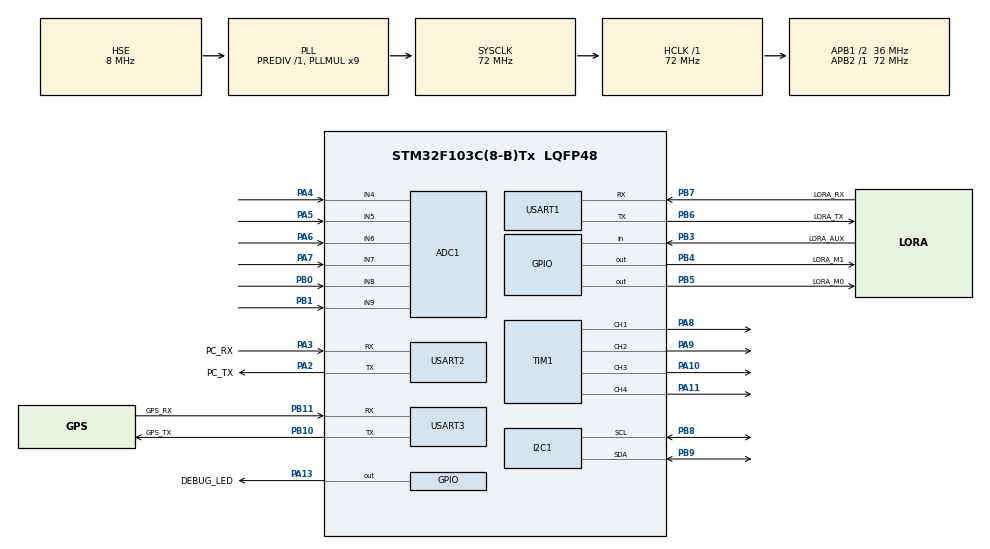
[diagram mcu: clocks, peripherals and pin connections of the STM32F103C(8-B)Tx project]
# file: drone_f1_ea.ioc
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ADC1.Channel-0\#ChannelRegularConversion=ADC_CHANNEL_4
ADC1.NbrOfConversion=1
ADC1.NbrOfConversionFlag=1
ADC1.Rank-0\#ChannelRegularConversion=1
ADC1.SamplingTime-0\#ChannelRegularConversion=ADC_SAMPLETIME_239CYCLES_5
ADC1.master=1
Dma.I2C1_RX.3.Direction=DMA_PERIPH_TO_MEMORY
Dma.I2C1_RX.3.Instance=DMA1_Channel7
Dma.I2C1_RX.3.MemDataAlignment=DMA_MDATAALIGN_BYTE
Dma.I2C1_RX.3.MemInc=DMA_MINC_ENABLE
Dma.I2C1_RX.3.Mode=DMA_NORMAL
Dma.I2C1_RX.3.PeriphDataAlignment=DMA_PDATAALIGN_BYTE
Dma.I2C1_RX.3.PeriphInc=DMA_PINC_DISABLE
Dma.I2C1_RX.3.Priority=DMA_PRIORITY_LOW
Dma.Request0=USART1_RX
Dma.Request1=USART2_RX
Dma.Request2=USART3_RX
Dma.Request3=I2C1_RX
Dma.USART1_RX.0.Direction=DMA_PERIPH_TO_MEMORY
Dma.USART1_RX.0.Instance=DMA1_Channel5
Dma.USART1_RX.0.MemDataAlignment=DMA_MDATAALIGN_BYTE
Dma.USART1_RX.0.MemInc=DMA_MINC_ENABLE
Dma.USART1_RX.0.Mode=DMA_CIRCULAR
Dma.USART1_RX.0.PeriphDataAlignment=DMA_PDATAALIGN_BYTE
Dma.USART1_RX.0.PeriphInc=DMA_PINC_DISABLE
Dma.USART1_RX.0.Priority=DMA_PRIORITY_LOW
Dma.USART2_RX.1.Direction=DMA_PERIPH_TO_MEMORY
Dma.USART2_RX.1.Instance=DMA1_Channel6
Dma.USART2_RX.1.MemDataAlignment=DMA_MDATAALIGN_BYTE
Dma.USART2_RX.1.MemInc=DMA_MINC_ENABLE
Dma.USART2_RX.1.Mode=DMA_CIRCULAR
Dma.USART2_RX.1.PeriphDataAlignment=DMA_PDATAALIGN_BYTE
Dma.USART2_RX.1.PeriphInc=DMA_PINC_DISABLE
Dma.USART2_RX.1.Priority=DMA_PRIORITY_LOW
Dma.USART3_RX.2.Direction=DMA_PERIPH_TO_MEMORY
Dma.USART3_RX.2.Instance=DMA1_Channel3
Dma.USART3_RX.2.MemDataAlignment=DMA_MDATAALIGN_BYTE
Dma.USART3_RX.2.MemInc=DMA_MINC_ENABLE
Dma.USART3_RX.2.Mode=DMA_CIRCULAR
Dma.USART3_RX.2.PeriphDataAlignment=DMA_PDATAALIGN_BYTE
Dma.USART3_RX.2.PeriphInc=DMA_PINC_DISABLE
Dma.USART3_RX.2.Priority=DMA_PRIORITY_LOW
FREERTOS.BinarySemaphores01=pc_rx_smphr,Dynamic,NULL;lora_rx_smphr,Dynamic,NULL;mpu9265_smphr,Dynamic,NULL;lora_tx_smphr,Dynamic,NULL
FREERTOS.Queues01=pc_rx_q,16,uart_data_t,0,Dynamic,NULL,NULL;pc_tx_q,16,uart_data_t,0,Dynamic,NULL,NULL;lora_rx_q,16,uart_data_t,0,Dynamic,NULL,NULL;lora_tx_q,16,uart_data_t,0,Dynamic,NULL,NULL
FREERTOS.Tasks01=periodicTask,-2,64,PeriodicTask,As weak,NULL,Dynamic,NULL,NULL;gpsTask,-1,64,GPSTask,As weak,NULL,Dynamic,NULL,NULL;motorControlTas,1,64,MotorControlTask,As weak,NULL,Dynamic,NULL,NULL;mpu9265Task,0,128,MPU9265Task,As weak,NULL,Dynamic,NULL,NULL;loraRxManager,2,128,LORARxManager,As weak,NULL,Dynamic,NULL,NULL;loraTxManager,1,64,LORATxManager,As weak,NULL,Dynamic,NULL,NULL;loraCommManager,2,64,LORACommunicationManager,As weak,NULL,Dynamic,NULL,NULL;pcRxManager,2,128,PCRxManager,As weak,NULL,Dynamic,NULL,NULL;pcTxManager,0,64,PCTxManager,As weak,NULL,Dynamic,NULL,NULL;pcCommManager,1,64,PcCommunicationManager,As weak,NULL,Dynamic,NULL,NULL;batteryTask,-2,64,BatteryTask,As weak,NULL,Dynamic,NULL,NULL
FREERTOS.configCHECK_FOR_STACK_OVERFLOW=0
FREERTOS.configMINIMAL_STACK_SIZE=64
FREERTOS.configTOTAL_HEAP_SIZE=6144
I2C1.I2C_Mode=I2C_Fast
Mcu.Family=STM32F1
Mcu.Name=STM32F103C(8-B)Tx
Mcu.Package=LQFP48
NVIC.DMA1_Channel3_IRQn=true\:5\:0\:false\:false\:true\:true\:false\:true
NVIC.DMA1_Channel5_IRQn=true\:5\:0\:false\:false\:true\:true\:false\:true
NVIC.DMA1_Channel6_IRQn=true\:5\:0\:false\:false\:true\:true\:false\:true
NVIC.DMA1_Channel7_IRQn=true\:5\:0\:false\:false\:true\:true\:false\:true
NVIC.I2C1_EV_IRQn=true\:5\:0\:false\:false\:true\:true\:true\:true
NVIC.PriorityGroup=NVIC_PRIORITYGROUP_4
NVIC.TIM4_IRQn=true\:0\:0\:false\:false\:true\:false\:false\:true
NVIC.TimeBase=TIM4_IRQn
NVIC.TimeBaseIP=TIM4
NVIC.USART1_IRQn=true\:8\:0\:true\:false\:true\:false\:true\:true
NVIC.USART2_IRQn=true\:9\:0\:true\:false\:true\:false\:true\:true
PA10.Signal=S_TIM1_CH3
PA11.Signal=S_TIM1_CH4
PA13.GPIO_Label=DEBUG_LED
PA13.Signal=GPIO_Output
PA2.GPIO_Label=PC_TX
PA2.Mode=Asynchronous
PA2.Signal=USART2_TX
PA3.GPIO_Label=PC_RX
PA3.Mode=Asynchronous
PA3.Signal=USART2_RX
PA4.Signal=ADCx_IN4
PA5.Signal=ADCx_IN5
PA6.Signal=ADCx_IN6
PA7.Signal=ADCx_IN7
PA8.Signal=S_TIM1_CH1
PA9.Signal=S_TIM1_CH2
PB0.Signal=ADCx_IN8
PB1.Signal=ADCx_IN9
PB10.GPIO_Label=GPS_TX
PB10.Mode=Asynchronous
PB10.Signal=USART3_TX
PB11.GPIO_Label=GPS_RX
PB11.Mode=Asynchronous
PB11.Signal=USART3_RX
PB3.GPIO_Label=LORA_AUX
PB3.Signal=GPIO_Input
PB4.GPIO_Label=LORA_M1
PB4.Signal=GPIO_Output
PB5.GPIO_Label=LORA_M0
PB5.Signal=GPIO_Output
PB6.GPIO_Label=LORA_TX
PB6.Mode=Asynchronous
PB6.Signal=USART1_TX
PB7.GPIO_Label=LORA_RX
PB7.Mode=Asynchronous
PB7.Signal=USART1_RX
PB8.Mode=I2C
PB8.Signal=I2C1_SCL
PB9.GPIO_Mode=GPIO_MODE_AF_OD
PB9.Mode=I2C
PB9.Signal=I2C1_SDA
PD0-OSC_IN.Mode=HSE-External-Oscillator
PD0-OSC_IN.Signal=RCC_OSC_IN
PD1-OSC_OUT.Mode=HSE-External-Oscillator
PD1-OSC_OUT.Signal=RCC_OSC_OUT
ProjectManager.HeapSize=0x200
ProjectManager.StackSize=0x400
ProjectManager.TargetToolchain=STM32CubeIDE
RCC.ADCPresc=RCC_ADCPCLK2_DIV8
RCC.AHBFreq_Value=72000000
RCC.APB1CLKDivider=RCC_HCLK_DIV2
RCC.APB1Freq_Value=36000000
RCC.APB1TimFreq_Value=72000000
RCC.APB2Freq_Value=72000000
RCC.APB2TimFreq_Value=72000000
RCC.HCLKFreq_Value=72000000
RCC.PLLMUL=RCC_PLL_MUL9
RCC.PLLSourceVirtual=RCC_PLLSOURCE_HSE
RCC.SYSCLKFreq_VALUE=72000000
RCC.SYSCLKSource=RCC_SYSCLKSOURCE_PLLCLK
RCC.USBFreq_Value=72000000
SH.ADCx_IN4.0=ADC1_IN4,IN4
SH.ADCx_IN5.0=ADC1_IN5,IN5
SH.ADCx_IN6.0=ADC1_IN6,IN6
SH.ADCx_IN7.0=ADC1_IN7,IN7
SH.ADCx_IN8.0=ADC1_IN8,IN8
SH.ADCx_IN9.0=ADC1_IN9,IN9
SH.S_TIM1_CH1.0=TIM1_CH1,PWM Generation1 CH1
SH.S_TIM1_CH2.0=TIM1_CH2,PWM Generation2 CH2
SH.S_TIM1_CH3.0=TIM1_CH3,PWM Generation3 CH3
SH.S_TIM1_CH4.0=TIM1_CH4,PWM Generation4 CH4
TIM1.Channel-PWM\ Generation1\ CH1=TIM_CHANNEL_1
TIM1.Channel-PWM\ Generation2\ CH2=TIM_CHANNEL_2
TIM1.Channel-PWM\ Generation3\ CH3=TIM_CHANNEL_3
TIM1.Channel-PWM\ Generation4\ CH4=TIM_CHANNEL_4
USART1.VirtualMode=VM_ASYNC
USART2.VirtualMode=VM_ASYNC
USART3.VirtualMode=VM_ASYNC
VP_FREERTOS_VS_CMSIS_V1.Mode=CMSIS_V1
VP_SYS_VS_ND.Mode=No_Debug
VP_SYS_VS_tim4.Mode=TIM4
board=custom

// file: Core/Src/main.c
/* USER CODE BEGIN Header */
/**
  ******************************************************************************
  * @file           : main.c
  * @brief          : Main program body
  ******************************************************************************
  * @attention
  *
  * <h2><center>&copy; Copyright (c) 2020 STMicroelectronics.
  * All rights reserved.</center></h2>
  *
  * This software component is licensed by ST under BSD 3-Clause license,
  * the "License"; You may not use this file except in compliance with the
  * License. You may obtain a copy of the License at:
  *                        opensource.org/licenses/BSD-3-Clause
  *
  ******************************************************************************
  */
/* USER CODE END Header */
#include "main.h"
#include "cmsis_os.h"

ADC_HandleTypeDef hadc1;

I2C_HandleTypeDef hi2c1;
DMA_HandleTypeDef hdma_i2c1_rx;

TIM_HandleTypeDef htim1;

UART_HandleTypeDef huart1;
UART_HandleTypeDef huart2;
UART_HandleTypeDef huart3;
DMA_HandleTypeDef hdma_usart1_rx;
DMA_HandleTypeDef hdma_usart2_rx;
DMA_HandleTypeDef hdma_usart3_rx;

osThreadId periodicTaskHandle;
osThreadId gpsTaskHandle;
osThreadId motorControlTasHandle;
osThreadId mpu9265TaskHandle;
osThreadId loraRxManagerHandle;
osThreadId loraTxManagerHandle;
osThreadId loraCommManagerHandle;
osThreadId pcRxManagerHandle;
osThreadId pcTxManagerHandle;
osThreadId pcCommManagerHandle;
osThreadId batteryTaskHandle;
osMessageQId pc_rx_qHandle;
osMessageQId pc_tx_qHandle;
osMessageQId lora_rx_qHandle;
osMessageQId lora_tx_qHandle;
osSemaphoreId pc_rx_smphrHandle;
osSemaphoreId lora_rx_smphrHandle;
osSemaphoreId mpu9265_smphrHandle;
osSemaphoreId lora_tx_smphrHandle;

void SystemClock_Config(void);
static void MX_GPIO_Init(void);
static void MX_DMA_Init(void);
static void MX_TIM1_Init(void);
static void MX_USART1_UART_Init(void);
static void MX_USART2_UART_Init(void);
static void MX_USART3_UART_Init(void);
static void MX_I2C1_Init(void);
static void MX_ADC1_Init(void);
void PeriodicTask(void const * argument);
void GPSTask(void const * argument);
void MotorControlTask(void const * argument);
void MPU9265Task(void const * argument);
void LORARxManager(void const * argument);
void LORATxManager(void const * argument);
void LORACommunicationManager(void const * argument);
void PCRxManager(void const * argument);
void PCTxManager(void const * argument);
void PcCommunicationManager(void const * argument);
void BatteryTask(void const * argument);

int main(void)
{

  /* MCU Configuration--------------------------------------------------------*/

  /* Reset of all peripherals, Initializes the Flash interface and the Systick. */
  HAL_Init();

  /* Configure the system clock */
  SystemClock_Config();

  /* Initialize all configured peripherals */
  MX_GPIO_Init();
  MX_DMA_Init();
  MX_TIM1_Init();
  MX_USART1_UART_Init();
  MX_USART2_UART_Init();
  MX_USART3_UART_Init();
  MX_I2C1_Init();
  MX_ADC1_Init();

  /* Create the semaphores(s) */
  /* definition and creation of pc_rx_smphr */
  osSemaphoreDef(pc_rx_smphr);
  pc_rx_smphrHandle = osSemaphoreCreate(osSemaphore(pc_rx_smphr), 1);

  /* definition and creation of lora_rx_smphr */
  osSemaphoreDef(lora_rx_smphr);
  lora_rx_smphrHandle = osSemaphoreCreate(osSemaphore(lora_rx_smphr), 1);

  /* definition and creation of mpu9265_smphr */
  osSemaphoreDef(mpu9265_smphr);
  mpu9265_smphrHandle = osSemaphoreCreate(osSemaphore(mpu9265_smphr), 1);

  /* definition and creation of lora_tx_smphr */
  osSemaphoreDef(lora_tx_smphr);
  lora_tx_smphrHandle = osSemaphoreCreate(osSemaphore(lora_tx_smphr), 1);

  /* Create the queue(s) */
  /* definition and creation of pc_rx_q */
  osMessageQDef(pc_rx_q, 16, uart_data_t);
  pc_rx_qHandle = osMessageCreate(osMessageQ(pc_rx_q), NULL);

  /* definition and creation of pc_tx_q */
  osMessageQDef(pc_tx_q, 16, uart_data_t);
  pc_tx_qHandle = osMessageCreate(osMessageQ(pc_tx_q), NULL);

  /* definition and creation of lora_rx_q */
  osMessageQDef(lora_rx_q, 16, uart_data_t);
  lora_rx_qHandle = osMessageCreate(osMessageQ(lora_rx_q), NULL);

  /* definition and creation of lora_tx_q */
  osMessageQDef(lora_tx_q, 16, uart_data_t);
  lora_tx_qHandle = osMessageCreate(osMessageQ(lora_tx_q), NULL);

  /* Create the thread(s) */
  /* definition and creation of periodicTask */
  osThreadDef(periodicTask, PeriodicTask, osPriorityLow, 0, 64);
  periodicTaskHandle = osThreadCreate(osThread(periodicTask), NULL);

  /* definition and creation of gpsTask */
  osThreadDef(gpsTask, GPSTask, osPriorityBelowNormal, 0, 64);
  gpsTaskHandle = osThreadCreate(osThread(gpsTask), NULL);

  /* definition and creation of motorControlTas */
  osThreadDef(motorControlTas, MotorControlTask, osPriorityAboveNormal, 0, 64);
  motorControlTasHandle = osThreadCreate(osThread(motorControlTas), NULL);

  /* definition and creation of mpu9265Task */
  osThreadDef(mpu9265Task, MPU9265Task, osPriorityNormal, 0, 128);
  mpu9265TaskHandle = osThreadCreate(osThread(mpu9265Task), NULL);

  /* definition and creation of loraRxManager */
  osThreadDef(loraRxManager, LORARxManager, osPriorityHigh, 0, 128);
  loraRxManagerHandle = osThreadCreate(osThread(loraRxManager), NULL);

  /* definition and creation of loraTxManager */
  osThreadDef(loraTxManager, LORATxManager, osPriorityAboveNormal, 0, 64);
  loraTxManagerHandle = osThreadCreate(osThread(loraTxManager), NULL);

  /* definition and creation of loraCommManager */
  osThreadDef(loraCommManager, LORACommunicationManager, osPriorityHigh, 0, 64);
  loraCommManagerHandle = osThreadCreate(osThread(loraCommManager), NULL);

  /* definition and creation of pcRxManager */
  osThreadDef(pcRxManager, PCRxManager, osPriorityHigh, 0, 128);
  pcRxManagerHandle = osThreadCreate(osThread(pcRxManager), NULL);

  /* definition and creation of pcTxManager */
  osThreadDef(pcTxManager, PCTxManager, osPriorityNormal, 0, 64);
  pcTxManagerHandle = osThreadCreate(osThread(pcTxManager), NULL);

  /* definition and creation of pcCommManager */
  osThreadDef(pcCommManager, PcCommunicationManager, osPriorityAboveNormal, 0, 64);
  pcCommManagerHandle = osThreadCreate(osThread(pcCommManager), NULL);

  /* definition and creation of batteryTask */
  osThreadDef(batteryTask, BatteryTask, osPriorityLow, 0, 64);
  batteryTaskHandle = osThreadCreate(osThread(batteryTask), NULL);

  /* USER CODE BEGIN RTOS_THREADS */
  /* add threads, ... */
  //Setting LORA to normal mode
  HAL_GPIO_WritePin(LORA_M0_GPIO_Port, LORA_M0_Pin, 0);
  HAL_GPIO_WritePin(LORA_M1_GPIO_Port, LORA_M1_Pin, 0);
  HAL_Delay(50);
	HAL_NVIC_SetPriority(TIM4_IRQn, 15, 0);	/* IRQ priority of system timer is set to lowest */
	HAL_UART_Transmit(&HUART_PC, (uint8_t *) "init", 4, 0xFF);
  /* USER CODE END RTOS_THREADS */

  /* Start scheduler */
  osKernelStart();

  /* We should never get here as control is now taken by the scheduler */
  /* Infinite loop */
  while (1)
  {

  }
}

void SystemClock_Config(void)
{
  RCC_OscInitTypeDef RCC_OscInitStruct = {0};
  RCC_ClkInitTypeDef RCC_ClkInitStruct = {0};
  RCC_PeriphCLKInitTypeDef PeriphClkInit = {0};

  /** Initializes the RCC Oscillators according to the specified parameters
  * in the RCC_OscInitTypeDef structure.
  */
  RCC_OscInitStruct.OscillatorType = RCC_OSCILLATORTYPE_HSE;
  RCC_OscInitStruct.HSEState = RCC_HSE_ON;
  RCC_OscInitStruct.HSEPredivValue = RCC_HSE_PREDIV_DIV1;
  RCC_OscInitStruct.HSIState = RCC_HSI_ON;
  RCC_OscInitStruct.PLL.PLLState = RCC_PLL_ON;
  RCC_OscInitStruct.PLL.PLLSource = RCC_PLLSOURCE_HSE;
  RCC_OscInitStruct.PLL.PLLMUL = RCC_PLL_MUL9;
  if (HAL_RCC_OscConfig(&RCC_OscInitStruct) != HAL_OK)
  {
    Error_Handler();
  }
  /** Initializes the CPU, AHB and APB buses clocks
  */
  RCC_ClkInitStruct.ClockType = RCC_CLOCKTYPE_HCLK|RCC_CLOCKTYPE_SYSCLK
                              |RCC_CLOCKTYPE_PCLK1|RCC_CLOCKTYPE_PCLK2;
  RCC_ClkInitStruct.SYSCLKSource = RCC_SYSCLKSOURCE_PLLCLK;
  RCC_ClkInitStruct.AHBCLKDivider = RCC_SYSCLK_DIV1;
  RCC_ClkInitStruct.APB1CLKDivider = RCC_HCLK_DIV2;
  RCC_ClkInitStruct.APB2CLKDivider = RCC_HCLK_DIV1;

  if (HAL_RCC_ClockConfig(&RCC_ClkInitStruct, FLASH_LATENCY_2) != HAL_OK)
  {
    Error_Handler();
  }
  PeriphClkInit.PeriphClockSelection = RCC_PERIPHCLK_ADC;
  PeriphClkInit.AdcClockSelection = RCC_ADCPCLK2_DIV8;
  if (HAL_RCCEx_PeriphCLKConfig(&PeriphClkInit) != HAL_OK)
  {
    Error_Handler();
  }
}

static void MX_ADC1_Init(void)
{

  ADC_ChannelConfTypeDef sConfig = {0};

  /** Common config
  */
  hadc1.Instance = ADC1;
  hadc1.Init.ScanConvMode = ADC_SCAN_DISABLE;
  hadc1.Init.ContinuousConvMode = DISABLE;
  hadc1.Init.DiscontinuousConvMode = DISABLE;
  hadc1.Init.ExternalTrigConv = ADC_SOFTWARE_START;
  hadc1.Init.DataAlign = ADC_DATAALIGN_RIGHT;
  hadc1.Init.NbrOfConversion = 1;
  if (HAL_ADC_Init(&hadc1) != HAL_OK)
  {
    Error_Handler();
  }
  /** Configure Regular Channel
  */
  sConfig.Channel = ADC_CHANNEL_4;
  sConfig.Rank = ADC_REGULAR_RANK_1;
  sConfig.SamplingTime = ADC_SAMPLETIME_239CYCLES_5;
  if (HAL_ADC_ConfigChannel(&hadc1, &sConfig) != HAL_OK)
  {
    Error_Handler();
  }

}

static void MX_I2C1_Init(void)
{

  hi2c1.Instance = I2C1;
  hi2c1.Init.ClockSpeed = 400000;
  hi2c1.Init.DutyCycle = I2C_DUTYCYCLE_2;
  hi2c1.Init.OwnAddress1 = 0;
  hi2c1.Init.AddressingMode = I2C_ADDRESSINGMODE_7BIT;
  hi2c1.Init.DualAddressMode = I2C_DUALADDRESS_DISABLE;
  hi2c1.Init.OwnAddress2 = 0;
  hi2c1.Init.GeneralCallMode = I2C_GENERALCALL_DISABLE;
  hi2c1.Init.NoStretchMode = I2C_NOSTRETCH_DISABLE;
  if (HAL_I2C_Init(&hi2c1) != HAL_OK)
  {
    Error_Handler();
  }

}

static void MX_TIM1_Init(void)
{

  TIM_MasterConfigTypeDef sMasterConfig = {0};
  TIM_OC_InitTypeDef sConfigOC = {0};
  TIM_BreakDeadTimeConfigTypeDef sBreakDeadTimeConfig = {0};

  htim1.Instance = TIM1;
  htim1.Init.Prescaler = 0;
  htim1.Init.CounterMode = TIM_COUNTERMODE_UP;
  htim1.Init.Period = 65535;
  htim1.Init.ClockDivision = TIM_CLOCKDIVISION_DIV1;
  htim1.Init.RepetitionCounter = 0;
  htim1.Init.AutoReloadPreload = TIM_AUTORELOAD_PRELOAD_DISABLE;
  if (HAL_TIM_PWM_Init(&htim1) != HAL_OK)
  {
    Error_Handler();
  }
  sMasterConfig.MasterOutputTrigger = TIM_TRGO_RESET;
  sMasterConfig.MasterSlaveMode = TIM_MASTERSLAVEMODE_DISABLE;
  if (HAL_TIMEx_MasterConfigSynchronization(&htim1, &sMasterConfig) != HAL_OK)
  {
    Error_Handler();
  }
  sConfigOC.OCMode = TIM_OCMODE_PWM1;
  sConfigOC.Pulse = 0;
  sConfigOC.OCPolarity = TIM_OCPOLARITY_HIGH;
  sConfigOC.OCNPolarity = TIM_OCNPOLARITY_HIGH;
  sConfigOC.OCFastMode = TIM_OCFAST_DISABLE;
  sConfigOC.OCIdleState = TIM_OCIDLESTATE_RESET;
  sConfigOC.OCNIdleState = TIM_OCNIDLESTATE_RESET;
  if (HAL_TIM_PWM_ConfigChannel(&htim1, &sConfigOC, TIM_CHANNEL_1) != HAL_OK)
  {
    Error_Handler();
  }
  if (HAL_TIM_PWM_ConfigChannel(&htim1, &sConfigOC, TIM_CHANNEL_2) != HAL_OK)
  {
    Error_Handler();
  }
  if (HAL_TIM_PWM_ConfigChannel(&htim1, &sConfigOC, TIM_CHANNEL_3) != HAL_OK)
  {
    Error_Handler();
  }
  if (HAL_TIM_PWM_ConfigChannel(&htim1, &sConfigOC, TIM_CHANNEL_4) != HAL_OK)
  {
    Error_Handler();
  }
  sBreakDeadTimeConfig.OffStateRunMode = TIM_OSSR_DISABLE;
  sBreakDeadTimeConfig.OffStateIDLEMode = TIM_OSSI_DISABLE;
  sBreakDeadTimeConfig.LockLevel = TIM_LOCKLEVEL_OFF;
  sBreakDeadTimeConfig.DeadTime = 0;
  sBreakDeadTimeConfig.BreakState = TIM_BREAK_DISABLE;
  sBreakDeadTimeConfig.BreakPolarity = TIM_BREAKPOLARITY_HIGH;
  sBreakDeadTimeConfig.AutomaticOutput = TIM_AUTOMATICOUTPUT_DISABLE;
  if (HAL_TIMEx_ConfigBreakDeadTime(&htim1, &sBreakDeadTimeConfig) != HAL_OK)
  {
    Error_Handler();
  }
  HAL_TIM_MspPostInit(&htim1);

}

static void MX_USART1_UART_Init(void)
{

  huart1.Instance = USART1;
  huart1.Init.BaudRate = 115200;
  huart1.Init.WordLength = UART_WORDLENGTH_8B;
  huart1.Init.StopBits = UART_STOPBITS_1;
  huart1.Init.Parity = UART_PARITY_NONE;
  huart1.Init.Mode = UART_MODE_TX_RX;
  huart1.Init.HwFlowCtl = UART_HWCONTROL_NONE;
  huart1.Init.OverSampling = UART_OVERSAMPLING_16;
  if (HAL_UART_Init(&huart1) != HAL_OK)
  {
    Error_Handler();
  }

}

static void MX_USART2_UART_Init(void)
{

  huart2.Instance = USART2;
  huart2.Init.BaudRate = 115200;
  huart2.Init.WordLength = UART_WORDLENGTH_8B;
  huart2.Init.StopBits = UART_STOPBITS_1;
  huart2.Init.Parity = UART_PARITY_NONE;
  huart2.Init.Mode = UART_MODE_TX_RX;
  huart2.Init.HwFlowCtl = UART_HWCONTROL_NONE;
  huart2.Init.OverSampling = UART_OVERSAMPLING_16;
  if (HAL_UART_Init(&huart2) != HAL_OK)
  {
    Error_Handler();
  }

}

static void MX_USART3_UART_Init(void)
{

  huart3.Instance = USART3;
  huart3.Init.BaudRate = 115200;
  huart3.Init.WordLength = UART_WORDLENGTH_8B;
  huart3.Init.StopBits = UART_STOPBITS_1;
  huart3.Init.Parity = UART_PARITY_NONE;
  huart3.Init.Mode = UART_MODE_TX_RX;
  huart3.Init.HwFlowCtl = UART_HWCONTROL_NONE;
  huart3.Init.OverSampling = UART_OVERSAMPLING_16;
  if (HAL_UART_Init(&huart3) != HAL_OK)
  {
    Error_Handler();
  }

}

static void MX_DMA_Init(void)
{

  /* DMA controller clock enable */
  __HAL_RCC_DMA1_CLK_ENABLE();

  /* DMA interrupt init */
  /* DMA1_Channel3_IRQn interrupt configuration */
  HAL_NVIC_SetPriority(DMA1_Channel3_IRQn, 5, 0);
  HAL_NVIC_EnableIRQ(DMA1_Channel3_IRQn);
  /* DMA1_Channel5_IRQn interrupt configuration */
  HAL_NVIC_SetPriority(DMA1_Channel5_IRQn, 5, 0);
  HAL_NVIC_EnableIRQ(DMA1_Channel5_IRQn);
  /* DMA1_Channel6_IRQn interrupt configuration */
  HAL_NVIC_SetPriority(DMA1_Channel6_IRQn, 5, 0);
  HAL_NVIC_EnableIRQ(DMA1_Channel6_IRQn);
  /* DMA1_Channel7_IRQn interrupt configuration */
  HAL_NVIC_SetPriority(DMA1_Channel7_IRQn, 5, 0);
  HAL_NVIC_EnableIRQ(DMA1_Channel7_IRQn);

}

static void MX_GPIO_Init(void)
{
  GPIO_InitTypeDef GPIO_InitStruct = {0};

  /* GPIO Ports Clock Enable */
  __HAL_RCC_GPIOD_CLK_ENABLE();
  __HAL_RCC_GPIOA_CLK_ENABLE();
  __HAL_RCC_GPIOB_CLK_ENABLE();

  /*Configure GPIO pin Output Level */
  HAL_GPIO_WritePin(DEBUG_LED_GPIO_Port, DEBUG_LED_Pin, GPIO_PIN_RESET);

  /*Configure GPIO pin Output Level */
  HAL_GPIO_WritePin(GPIOB, LORA_M1_Pin|LORA_M0_Pin, GPIO_PIN_RESET);

  /*Configure GPIO pin : DEBUG_LED_Pin */
  GPIO_InitStruct.Pin = DEBUG_LED_Pin;
  GPIO_InitStruct.Mode = GPIO_MODE_OUTPUT_PP;
  GPIO_InitStruct.Pull = GPIO_NOPULL;
  GPIO_InitStruct.Speed = GPIO_SPEED_FREQ_LOW;
  HAL_GPIO_Init(DEBUG_LED_GPIO_Port, &GPIO_InitStruct);

  /*Configure GPIO pin : LORA_AUX_Pin */
  GPIO_InitStruct.Pin = LORA_AUX_Pin;
  GPIO_InitStruct.Mode = GPIO_MODE_INPUT;
  GPIO_InitStruct.Pull = GPIO_NOPULL;
  HAL_GPIO_Init(LORA_AUX_GPIO_Port, &GPIO_InitStruct);

  /*Configure GPIO pins : LORA_M1_Pin LORA_M0_Pin */
  GPIO_InitStruct.Pin = LORA_M1_Pin|LORA_M0_Pin;
  GPIO_InitStruct.Mode = GPIO_MODE_OUTPUT_PP;
  GPIO_InitStruct.Pull = GPIO_NOPULL;
  GPIO_InitStruct.Speed = GPIO_SPEED_FREQ_LOW;
  HAL_GPIO_Init(GPIOB, &GPIO_InitStruct);

}

__weak void PeriodicTask(void const * argument)
{
  for(;;)
  {
    osDelay(1);
  }
}

__weak void GPSTask(void const * argument)
{
  for(;;)
  {
    osDelay(1);
  }
}

__weak void MotorControlTask(void const * argument)
{
  for(;;)
  {
    osDelay(1);
  }
}

__weak void MPU9265Task(void const * argument)
{
  for(;;)
  {
    osDelay(1);
  }
}

__weak void LORARxManager(void const * argument)
{
  for(;;)
  {
    osDelay(1);
  }
}

__weak void LORATxManager(void const * argument)
{
  for(;;)
  {
    osDelay(1);
  }
}

__weak void LORACommunicationManager(void const * argument)
{
  for(;;)
  {
    osDelay(1);
  }
}

__weak void PCRxManager(void const * argument)
{
  for(;;)
  {
    osDelay(1);
  }
}

__weak void PCTxManager(void const * argument)
{
  for(;;)
  {
    osDelay(1);
  }
}

__weak void PcCommunicationManager(void const * argument)
{
  for(;;)
  {
    osDelay(1);
  }
}

__weak void BatteryTask(void const * argument)
{
  for(;;)
  {
    osDelay(1);
  }
}

void HAL_TIM_PeriodElapsedCallback(TIM_HandleTypeDef *htim)
{
  if (htim->Instance == TIM4) {
    HAL_IncTick();
  }
}

void Error_Handler(void)
{
}

/************************ (C) COPYRIGHT STMicroelectronics *****END OF FILE****/
